# A31G12x_series register map
Vendor: ABOV Semiconductor Co., Ltd.; Series: A31G12x_series; File version: 1.0
ARM 32-bit Cortex-M0+ Microcontroller based device, CPU clock up to 40MHz, etc.
CPU: CM0PLUS r0p1, little endian, no MPU, no FPU, VTOR, 2 interrupt priority bits
Registers are 32-bit, read-write, reset 0x0 unless marked. A register's access mark holds for its fields unless they carry their own. Offsets are from the block's base; lines under a group give offsets from that group; [hi:lo] are bit positions; {n}, {i} and the like mark numbered series; 'fields as' and 'values as' point back to an identical list; <NAME> marks a mode.

## Memory map
0x1FFFF000 CFGOPT0 size 0x80 — CONFIGURE OPTION AREA
0x1FFFF200 CFGOPT1 size 0x80 — CONFIGURE OPTION AREA
0x1FFFF400 CFGOPT2 size 0x80 — CONFIGURE OPTION AREA
0x1FFFF600 CFGOPT3 size 0x80 — CONFIGURE OPTION AREA
0x30000000 PA size 0x100 — General Port A
0x30000100 PB size 0x100 — General Port B
0x30000200 PC size 0x100 — General Port C
0x30000300 PD size 0x100 — General Port D
0x30000400 PE size 0x100 — General Port E
0x30000500 PF size 0x100 — General Port F
0x30001000 CRC size 0x20 — CYCLIC REDUNDANCY CHECK AND CHECKSUM
0x40001000 INT size 0x500 — Interrupt
0x40001800 SCUCG size 0x100 — CLCOK GENERATION
0x40001A00 WDT size 0x20 — WATCH-DOG TIMER
0x40001B00 FMC size 0x180 — FLASH MEMORY CONTROLLER
0x40002000 WT size 0x10 — WATCH TIMER
0x40002100 T10 size 0x100 — TIMER COUNTER 10/11/12/13/14/15/16
0x40002200 T11 size 0x100 — TIMER COUNTER 10/11/12/13/14/15/16
0x40002300 T12 size 0x100 — TIMER COUNTER 10/11/12/13/14/15/16
0x40002400 T30 size 0x40 — TIMER COUNTER 30
0x40002500 T20 size 0x20 — TIMER COUNTER 20/21
0x40002600 T21 size 0x20 — TIMER COUNTER 20/21
0x40002700 T13 size 0x100 — TIMER COUNTER 10/11/12/13/14/15/16
0x40002800 T14 size 0x100 — TIMER COUNTER 10/11/12/13/14/15/16
0x40002900 T15 size 0x100 — TIMER COUNTER 10/11/12/13/14/15/16
0x40002A00 T16 size 0x100 — TIMER COUNTER 10/11/12/13/14/15/16
0x40003000 ADC size 0x10 — 12-BIT A/D CONVERTER
0x40003800 USART10 size 0x100 — USART 10 (UART + SPI)
0x40003900 USART11 size 0x100 — USART 11 (UART + SPI)
0x40003A00 USART12 size 0x100 — USART 12 (UART + SPI)
0x40003B00 USART13 size 0x100 — USART 13 (UART + SPI)
0x40004000 UART0 size 0x100
0x40004100 UART1 size 0x100
0x40004800 I2C0 size 0x100
0x40004900 I2C1 size 0x100
0x40004A00 I2C2 size 0x100
0x40005000 LCD size 0x30 — LCD DRIVER/CONTROLLER
0x40005100 SCULV size 0x10 — LOW VOLTAGE INDICATOR(LVI) AND LOW VOLTAGE RESET(LVR)
0x4000F000 SCUCC size 0xD0 — CHIP CONFIGURATION
0xE000E010 xSysTick size 0x10 — SYSTEM TIMER
0xE000E100 xNVIC size 0x400 — NESTED VECTORED INTERRUPT CONTROLLER
0xE000ED00 xSCB size 0x30 — SYSTEM CONTROL BLOCK

## Interrupts
0 LVI (SCULV)
1 WUT (SCUCC)
2 WDT
3 EINT0 (INT)
4 EINT1 (INT)
5 EINT2 (INT)
6 EINT3 (INT)
7 TIMER10 (T10)
8 TIMER11 (T11)
9 TIMER12 (T12)
10 I2C0
11 USART10
12 WT
13 TIMER30 (T30)
14 I2C1
15 TIMER20 (T20)
16 TIMER21 (T21)
17 USART11
18 ADC
19 UART0
20 UART1
21 TIMER13 (T13)
22 TIMER14 (T14)
23 TIMER15 (T15)
24 TIMER16 (T16)
25 I2C2
26 USART12
27 USART13

## xSysTick — SYSTEM TIMER
Base 0xE000E010
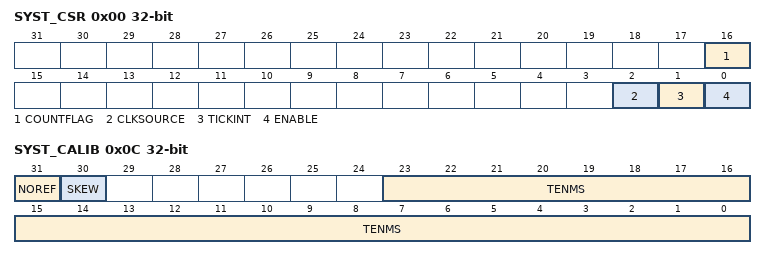
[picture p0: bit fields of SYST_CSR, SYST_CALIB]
0x00 SYST_CSR — SysTick Control and Status Register
  [16] COUNTFLAG — Returns 1 if timer counted to 0 since the last read of this register
  [2] CLKSOURCE — Selects the SysTick timer clock source
    0=EXT_REF_CLK (External reference clock); 1=PROCESSOR_CLK (Processor clock)
  [1] TICKINT — Enable SysTick exception request
    0=DISABLE_SYSTICK_EXCEPTION (Counting down to zero does not assert the SysTick exception request); 1=ENABLE_SYSTICK_EXCEPTION (Counting down to zero to asserts the SysTick exception request)
  [0] ENABLE — Enable the counter
    0=DISABLE_COUNTER (Counter disabled); 1=ENABLE_COUNTER (Counter enabled)
0x04 SYST_RVR — SysTick Reload Value Register
  [23:0] RELOAD — Value to load into the SYST_CVR when the counter is enabled and when it reaches 0. The range is 0x000001 to 0xFFFFFF.
0x08 SYST_CVR — SysTick Current Value Register
  [23:0] CURRENT — Reads return the current value of the SysTick counter. A write of any value clears the field to 0, and also clears the SYST_CSR.COUNTFLAG bit to 0.
0x0C SYST_CALIB ro — SysTick Calibration Value Register
  [31] NOREF — Indicates whether the device provides a reference clock to the processor
    0=PROVIDE_REF_CLK (Reference clock provided); 1=PROVIDE_NO_REF_CLK (No reference clock provided)
  [30] SKEW — Indicates whether the TENMS value is exact
    0=EXACT (TENMS value is exact); 1=INEXACT (TENMS value is inexact, or not given.)
  [23:0] TENMS — Reload value for 10ms (100Hz) timing, subject to system clock skew errors. If the value reads as zero, the calibration value is not known.

## Licence text in the file
ARM Limited (ARM) is supplying this software for use with Cortex-M processor based microcontroller, but can be equally used for other suitable processor architectures. This file can be freely distributed. Modifications to this file shall be clearly marked. . THIS SOFTWARE IS PROVIDED "AS IS". NO WARRANTIES, WHETHER EXPRESS, IMPLIED. OR STATUTORY, INCLUDING, BUT NOT LIMITED TO, IMPLIED WARRANTIES OF. MERCHANTABILITY AND FITNESS FOR A PARTICULAR PURPOSE APPLY TO THIS SOFTWARE. ARM SHALL NOT, IN ANY CIRCUMSTANCES, BE LIABLE FOR SPECIAL, INCIDENTAL, OR. CONSEQUENTIAL DAMAGES, FOR ANY REASON WHATSOEVER.

## Notices in the file
Copyright (C) 2012-2014 ARM Limited. All rights reserved.
Purpose: System Viewer Description (SVD) Example (Schema Version 1.1)
This is a description of a none-existent and incomplete device
for demonstration purposes only.
Redistribution and use in source and binary forms, with or without
modification, are permitted provided that the following conditions are met:
- Redistributions of source code must retain the above copyright
notice, this list of conditions and the following disclaimer.
- Redistributions in binary form must reproduce the above copyright
notice, this list of conditions and the following disclaimer in the
documentation and/or other materials provided with the distribution.
- Neither the name of ARM nor the names of its contributors may be used
to endorse or promote products derived from this software without
specific prior written permission.
THIS SOFTWARE IS PROVIDED BY THE COPYRIGHT HOLDERS AND CONTRIBUTORS "AS IS"
AND ANY EXPRESS OR IMPLIED WARRANTIES, INCLUDING, BUT NOT LIMITED TO, THE
ARE DISCLAIMED. IN NO EVENT SHALL COPYRIGHT HOLDERS AND CONTRIBUTORS BE
LIABLE FOR ANY DIRECT, INDIRECT, INCIDENTAL, SPECIAL, EXEMPLARY, OR
CONSEQUENTIAL DAMAGES (INCLUDING, BUT NOT LIMITED TO, PROCUREMENT OF
SUBSTITUTE GOODS OR SERVICES; LOSS OF USE, DATA, OR PROFITS; OR BUSINESS
INTERRUPTION) HOWEVER CAUSED AND ON ANY THEORY OF LIABILITY, WHETHER IN
CONTRACT, STRICT LIABILITY, OR TORT (INCLUDING NEGLIGENCE OR OTHERWISE)
ARISING IN ANY WAY OUT OF THE USE OF THIS SOFTWARE, EVEN IF ADVISED OF THE
POSSIBILITY OF SUCH DAMAGE.
